VERSION ""
NS_ :

BS_:
BU_:
BO_ 2147486754 Message2: 8 Vector__XXX
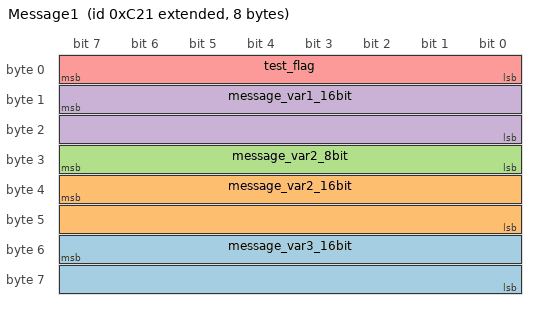
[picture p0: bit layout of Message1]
BO_ 2147486753 Message1: 8 Vector__XXX
SG_ message_var3_16bit : 55|16@0+ (1,0) [0|0] "" Vector__XXX
SG_ message_var2_16bit : 39|16@0+ (1,0) [0|0] "" Vector__XXX
SG_ message_var2_8bit : 31|8@0+ (1,0) [0|0] "" Vector__XXX
SG_ message_var1_16bit : 15|16@0+ (1,0) [0|0] "" Vector__XXX
SG_ test_flag : 7|8@0+ (1,0) [0|0] "" Vector__XXX
BA_DEF_ SG_  "SigType" ENUM  "Default","Range","RangeSigned","ASCII","Discrete","Control","ReferencePGN","DTC","StringDelimiter","StringLength","StringLengthControl";
BA_DEF_ SG_  "GenSigEVName" STRING ;
BA_DEF_ SG_  "GenSigILSupport" ENUM  "No","Yes";
BA_DEF_ SG_  "GenSigSendType" ENUM  "Cyclic","OnWrite","OnWriteWithRepetition","OnChange","OnChangeWithRepetition","IfActive","IfActiveWithRepetition","NoSigSendType";
BA_DEF_ BO_  "GenMsgILSupport" ENUM  "No","Yes";
BA_DEF_ BU_  "NmStationAddress" INT 0 255;
BA_DEF_ BO_  "GenMsgSendType" ENUM  "cyclic","NotUsed","IfActive","NotUsed","NotUsed","NotUsed","NotUsed","NotUsed","noMsgSendType";
BA_DEF_ BO_  "GenMsgRequestable" INT 0 1;
BA_DEF_  "DBName" STRING ;
BA_DEF_  "BusType" STRING ;
BA_DEF_  "ProtocolType" STRING ;
BA_DEF_ BO_  "VFrameFormat" ENUM  "StandardCAN","ExtendedCAN","reserved","J1939PG";
BA_DEF_DEF_  "SigType" "Default";
BA_DEF_DEF_  "GenSigEVName" "Env@Nodename_@Signame";
BA_DEF_DEF_  "GenSigILSupport" "Yes";
BA_DEF_DEF_  "GenSigSendType" "NoSigSendType";
BA_DEF_DEF_  "GenMsgILSupport" "Yes";
BA_DEF_DEF_  "NmStationAddress" 254;
BA_DEF_DEF_  "GenMsgSendType" "noMsgSendType";
BA_DEF_DEF_  "GenMsgRequestable" 1;
BA_DEF_DEF_  "DBName" "";
BA_DEF_DEF_  "BusType" "CAN";
BA_DEF_DEF_  "ProtocolType" "J1939";
BA_DEF_DEF_  "VFrameFormat" "J1939PG";
BA_ "DBName" "ECUTstInf";
